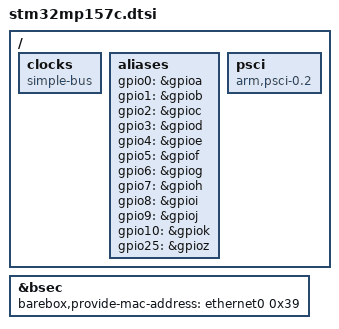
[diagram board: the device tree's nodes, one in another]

/ {
	clocks {
		/* Needed to let barebox find the clock nodes */
		compatible = "simple-bus";
	};

	aliases {
		gpio0 = &gpioa;
		gpio1 = &gpiob;
		gpio2 = &gpioc;
		gpio3 = &gpiod;
		gpio4 = &gpioe;
		gpio5 = &gpiof;
		gpio6 = &gpiog;
		gpio7 = &gpioh;
		gpio8 = &gpioi;
		gpio9 = &gpioj;
		gpio10 = &gpiok;
		gpio25 = &gpioz;
	};

	psci {
		compatible = "arm,psci-0.2";
	};
};

&bsec {
	barebox,provide-mac-address = <&ethernet0 0x39>;
};
